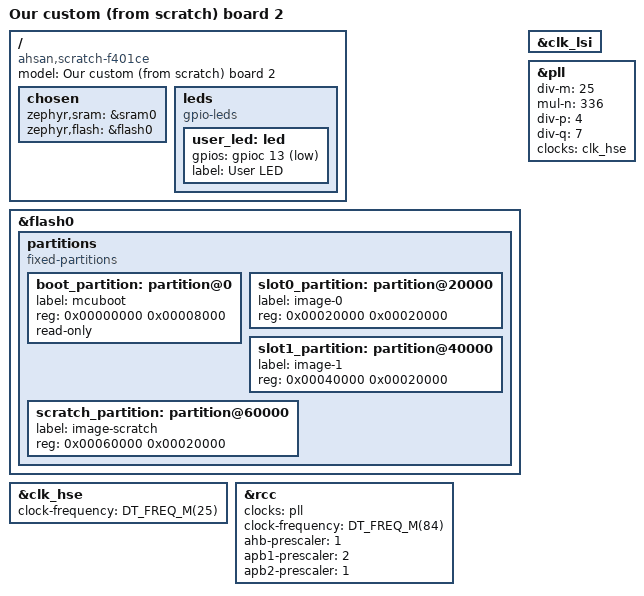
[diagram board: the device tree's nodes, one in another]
/dts-v1/;
#include <st/f4/stm32f401Xc.dtsi>
#include <st/f4/stm32f401c(d-e)ux-pinctrl.dtsi>
#include <zephyr/dt-bindings/input/input-event-codes.h>

/ {
    model = "Our custom (from scratch) board 2";
    compatible = "ahsan,scratch-f401ce";

	chosen {
		zephyr,sram = &sram0;
		zephyr,flash = &flash0;
	};

	leds {
		compatible = "gpio-leds";

		user_led: led {
			gpios = <&gpioc 13 GPIO_ACTIVE_LOW>;
			label = "User LED";
		};
	};
};

&flash0 {
	partitions {
		compatible = "fixed-partitions";
		#address-cells = <1>;
		#size-cells = <1>;

		boot_partition: partition@0 {
			label = "mcuboot";
			reg = <0x00000000 0x00008000>;
			read-only;
		};

		/*
		 * The flash starting at offset 0x00008000 and ending at
		 * offset 0x0001ffff (sectors 2 through 4) is reserved for
		 * use by the application.
		 */

		slot0_partition: partition@20000 {
			label = "image-0";
			reg = <0x00020000 0x00020000>;
		};

		slot1_partition: partition@40000 {
			label = "image-1";
			reg = <0x00040000 0x00020000>;
		};

		scratch_partition: partition@60000 {
			label = "image-scratch";
			reg = <0x00060000 0x00020000>;
		};
	};
};

&clk_lsi {
	status = "okay";
};

&clk_hse {
	clock-frequency = <DT_FREQ_M(25)>;
	status = "okay";
};

&pll {
	div-m = <25>;
	mul-n = <336>;
	div-p = <4>;
	div-q = <7>;
	clocks = <&clk_hse>;
	status = "okay";
};

&rcc {
	clocks = <&pll>;
	clock-frequency = <DT_FREQ_M(84)>;
	ahb-prescaler = <1>;
	apb1-prescaler = <2>;
	apb2-prescaler = <1>;
};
